# SA3_SS_PSILSS_0_PSILSS_44802000h register map
Vendor: Texas Instruments
Peripheral module from a debugger description file (folder AM275x).
Registers are 32-bit, read-only, reset 0x0 unless marked. A register's access mark holds for its fields unless they carry their own. Offsets are as the file gives them; lines under a group give offsets from that group; [hi:lo] are bit positions; {n}, {i} and the like mark numbered series; 'fields as' and 'values as' point back to an identical list; <NAME> marks a mode.

## psilss
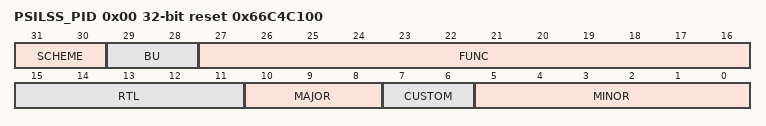
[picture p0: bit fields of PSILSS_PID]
0x00 PSILSS_PID reset 0x66C4C100 — The Revision Register contains the major and minor revisions for the module.
  [31:30] SCHEME — PID register scheme Reset Source: rst_mod_g_rst_n
  [29:28] BU — Business Unit: 10 = Processors Reset Source: rst_mod_g_rst_n
  [27:16] FUNC — Module ID Reset Source: rst_mod_g_rst_n
  [15:11] RTL — RTL revision. Will vary depending on release. Reset Source: rst_mod_g_rst_n
  [10:8] MAJOR — Major revision Reset Source: rst_mod_g_rst_n
  [7:6] CUSTOM — Custom Reset Source: rst_mod_g_rst_n
  [5:0] MINOR — Minor revision Reset Source: rst_mod_g_rst_n
0x04 PSILSS_CONFIG reset 0xC — The Config Register shows configured params.
  [15:0] ENDPOINTS — Number of endpoints supported. Reset Source: rst_mod_g_rst_n
0x10 PSILSS_EVENT rw reset 0xFFFF — The Event Register defines the event to produce for a link down event.
  [15:0] EVT — The event to produce. Reset Source: rst_mod_g_rst_n
0x20 PSILSS_LINK — The Link Register shows the current status of the endpoint links.
  [31:0] STATUS — The status of the endpoint links. Reset Source: rst_mod_g_rst_n
0x40 PSILSS_DOWN access not given — The Link Down Register shows which links are down for the endpoints.
  [31:0] STATUS — The down status of the endpoint links. Reset Source: rst_mod_g_rst_n (access R/W1TC)
